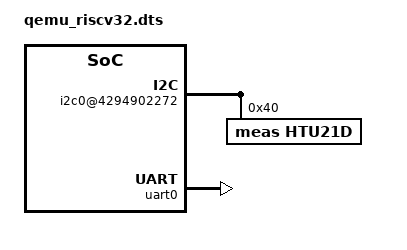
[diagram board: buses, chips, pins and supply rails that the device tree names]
/* SPDX-License-Identifier: Apache-2.0 */

/dts-v1/;

#include <qemu/virt-riscv32.dtsi>

/ {
	chosen {
		zephyr,console = &uart0;
		zephyr,shell-uart = &uart0;
		zephyr,sram = &ram0;
	};

	i2c0@4294902272 {
		compatible = "qemu,i2c_lattice";
		reg = <4294902272 61>;
		status = "okay";

		htu21d@40 {
		       compatible = "meas,htu21d";
		       label = "HTU21D";
		       reg = <0x40>;
		};
	};
};

&uart0 {
	status = "okay";
};
